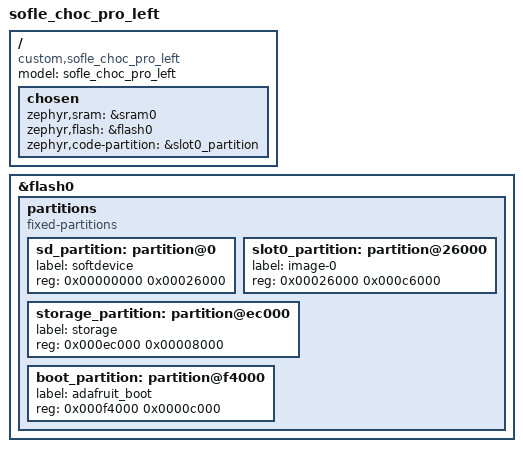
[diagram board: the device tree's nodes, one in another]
/dts-v1/;
#include <nordic/nrf52840_qiaa.dtsi>

/ {
    model = "sofle_choc_pro_left";
    compatible = "custom,sofle_choc_pro_left";

    chosen {
        zephyr,sram = &sram0;
        zephyr,flash = &flash0;
        zephyr,code-partition = &slot0_partition;
    };
};

&flash0 {
    partitions {
        compatible = "fixed-partitions";
        #address-cells = <1>;
        #size-cells = <1>;

        sd_partition: partition@0 {
            label = "softdevice";
            reg = <0x00000000 0x00026000>;
        };
        slot0_partition: partition@26000 {
            label = "image-0";
            reg = <0x00026000 0x000c6000>;
        };
        storage_partition: partition@ec000 {
            label = "storage";
            reg = <0x000ec000 0x00008000>;
        };
        boot_partition: partition@f4000 {
            label = "adafruit_boot";
            reg = <0x000f4000 0x0000c000>;
        };
    };
};
